# DMASS_PKTDMA_0_DMASS_PKTDMA_0_PKTDMA_FLOWRT_47200000h register map
Vendor: Texas Instruments
Peripheral module from a debugger description file (folder am62L).
Registers are 32-bit, access not given, reset 0x0 unless marked. A register's access mark holds for its fields unless they carry their own. Offsets are as the file gives them; lines under a group give offsets from that group; [hi:lo] are bit positions; {n}, {i} and the like mark numbered series; 'fields as' and 'values as' point back to an identical list; <NAME> marks a mode.

## DMASS_PKTDMA_0_PKTDMA_FLOWRT
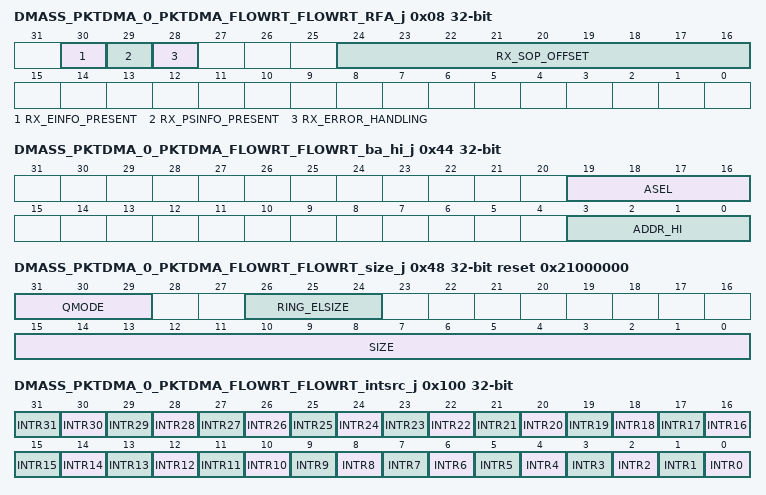
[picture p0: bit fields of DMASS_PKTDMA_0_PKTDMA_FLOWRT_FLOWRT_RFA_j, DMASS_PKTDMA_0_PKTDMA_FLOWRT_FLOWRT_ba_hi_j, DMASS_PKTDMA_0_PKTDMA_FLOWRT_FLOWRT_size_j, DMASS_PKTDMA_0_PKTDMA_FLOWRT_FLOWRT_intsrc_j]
0x08 DMASS_PKTDMA_0_PKTDMA_FLOWRT_FLOWRT_RFA_j rw — The Rx Flow N Configuration Register A contains static configuration information for the Rx DMA flow. The fields in this register can only be changed when all of the DMA channels that use this flow have been disabled. This register is an aliased version from the flow configuration register and is only visible if the alias bit is set in the RESRC register.
  [30] RX_EINFO_PRESENT — This bit controls whether or not the Extended Packet Info Block will be present in the Rx Packet Descriptor. If this bit is clear, the port DMA will clear the Extended Packet Info Present bit in the PD and will drop any Timestamp or SW Data words that are presented from the back end application. If this bit is set, the port DMA will set the Extended Packet Info Block Present bit in the PD and will copy any Timestamp or SW Data words that are presented across the Rx streaming interface into the Extended Packet Info Block words in the descriptor. If no Timestamp or SW Data words are presented from the back end application, the port DMA will overwrite the fields in the PD with zeroes. Reset Source: rst_mod_g_rst_n
  [29] RX_PSINFO_PRESENT — This bit controls whether or not the Protocol Specific words will be present in the Rx Packet Descriptor. If this bit is clear, the port DMA will set the PS word count to 0 in the PD and will drop any PS words that are presented from the back end application. If this bit is set, the port DMA will set the PS word count to the value given by the back end application and will copy the PS words from the back end application to the location Reset Source: rst_mod_g_rst_n
  [28] RX_ERROR_HANDLING — This bit controls the error handling mode for the flow and is only used when channel errors (i.e. descriptor starvation) occurs. 0 = Starvation errors result in dropping packet and incrementing dropped packet count. 1 = Starvation errors result in the channel waiting until descriptors are added to the free queue before the channel will be scheduled. Reset Source: rst_mod_g_rst_n
  [24:16] RX_SOP_OFFSET — This field specifies the number of bytes that are to be skipped in the SOP buffer before beginning to write the payload or protocol specific bytes(if they are in the sop buffer). This value must be less than the minimum size of a buffer in the system. Valid values are 0 - 255 bytes. The primary purpose of this field is to ensure that space is left in the descriptor to place the protocol specific information without overwriting or being overwritten by the Rx data. The secondary purpose of this field is to allow space to be left prior to the data in the descriptor in case header information needs to be added as the packet is passed thorough the system. Reset Source: rst_mod_g_rst_n
0x10 DMASS_PKTDMA_0_PKTDMA_FLOWRT_FLOWRT_fdb_j — The Ring N Doorbell Register is written by software to increment or decrement the number of entries on a Ring. One or more entries as specified by the entry_cnt field can be added to a ring with a single write operation.
  [7:0] ENTRY_CNT — Signed number of entries by which to increment the ring occupancy. For normal Tx Ring operation, this value should be a positive number. This occ value for the ring is increased by this value each time the doorbell register is written (occ absolute value will increase or decrease based on the sign of the ENTRY_CNT). Reset Source: rst_mod_g_rst_n (access NA/W)
0x18 DMASS_PKTDMA_0_PKTDMA_FLOWRT_FLOWRT_focc_j — The Ring N Occupancy Register can be read by software to determine the total number of valid entries on a ring. The contents of each of these registers are unary ORed in order to create a pending signal for the ring which can be used for triggering hardware operations and/or for generating interrupts to the host.
  [16:0] OCC — Total number of valid entries on the ring. This value is generally intended to be incremented by doorbell pokes from software and is decremented by the DMA engine as entries are completed. Reset Source: rst_mod_g_rst_n (access R/NA)
0x40 DMASS_PKTDMA_0_PKTDMA_FLOWRT_FLOWRT_ba_lo_j rw — The Ring Base Address Lo Register contains the 32 LSBs of the base address for the ring which is used to hand off pending work for the channel from the Host. The base address must be aligned to 0x8. A write to this register will reset the associated ring to clear the occupancies and reset the pointers. This register is an aliased version from the flow configuration register and is only visible if the alias bit is set in the RESRC register.
  [31:0] ADDR_LO — Ring base address (LSBs) Reset Source: rst_mod_g_rst_n
0x44 DMASS_PKTDMA_0_PKTDMA_FLOWRT_FLOWRT_ba_hi_j rw — The Ring Base Address Hi Register contains the 16 MSBs of the base address for the ring which is used to hand off pending work for the channel from the Host. The base address must be aligned to 0x8. A write to this register will reset the associated ring to clear the occupancies and reset the pointers. This register is only visible if the alias bit is set in the ring configuration register. This register is an aliased version from the flow configuration register and is only visible if the alias bit is set in the RESRC register.
  [19:16] ASEL — Ring base address select Reset Source: rst_mod_g_rst_n
  [3:0] ADDR_HI — Ring base address (MSBs) Reset Source: rst_mod_g_rst_n
0x48 DMASS_PKTDMA_0_PKTDMA_FLOWRT_FLOWRT_size_j reset 0x21000000 — The Ring Size Register contains the element count for the ring which is used to hand off pending work for the channel from the Host. A write to this register will reset the associated ring to clear the occupancies and reset the pointers. This register is only visible if the alias bit is set in the ring configuration register.
  [31:29] QMODE — Defines the mode for this ring or queue. 1 exposed ring mode with dual queues (forward/reverse) for SW direct access (access R/NA)
  [26:24] RING_ELSIZE — Ring Element size. This field is hardcode as 1 = 8 bytes. Reset Source: rst_mod_g_rst_n (access R/NA)
  [15:0] SIZE rw — This field configures the size of the ring in elements. Reset Source: rst_mod_g_rst_n
0x100 DMASS_PKTDMA_0_PKTDMA_FLOWRT_FLOWRT_intsrc_j — The Interrupt Source shows which of the rings that share the same interrupt as the current ring is setting the interrupt. This register will be the same for all the flows with the same aggregator. The bits are assigned based on the lowest flow number for the aggregator will be in bit 0 and each incremental above will be the next bit. So if flows 5-10 share an interrupt then if flow 5 has a non-zero Masked Cause Register bit 0 will be set. If a ring does not have an interrupt then only bit 0 will be used.
  [n] INTR{n} (n=0..31) — The ring associated with this flow has an active masked interrupt Reset Source: rst_mod_g_rst_n (access R/NA)
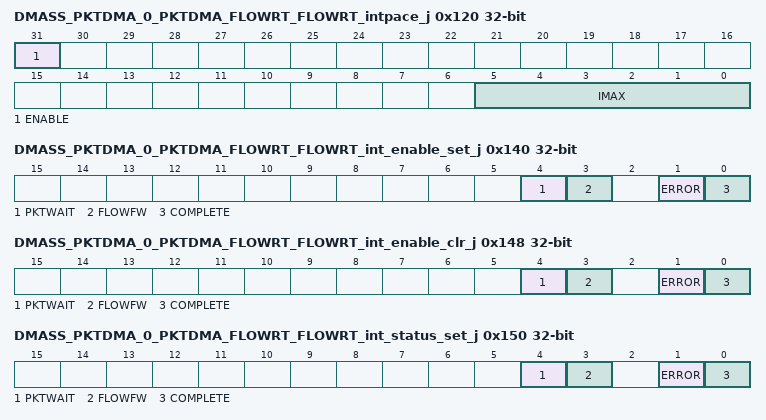
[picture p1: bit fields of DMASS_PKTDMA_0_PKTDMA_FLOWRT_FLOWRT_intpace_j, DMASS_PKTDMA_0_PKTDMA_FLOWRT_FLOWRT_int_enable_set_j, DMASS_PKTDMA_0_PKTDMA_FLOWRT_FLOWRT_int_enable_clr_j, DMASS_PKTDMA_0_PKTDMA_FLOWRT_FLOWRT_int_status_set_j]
0x120 DMASS_PKTDMA_0_PKTDMA_FLOWRT_FLOWRT_intpace_j rw — This register controls the interrupt pacing for the interrupt associated with this flow. This register will only be present if the interrupt supports pacing otherwise it is reserved
  [31] ENABLE — This enables the interrupt pacing module for this interrupt Reset Source: rst_mod_g_rst_n
  [5:0] IMAX — This is the maximum number of interrupts per millisecond generated if the pacing is enabled Reset Source: rst_mod_g_rst_n
0x140 DMASS_PKTDMA_0_PKTDMA_FLOWRT_FLOWRT_int_enable_set_j — The Interrupt Enable Set register is written by software to enable (i.e unmask) specified bits to allow their current status to be considered in the generation of the level sensitive interrupt that is generated by this ring.
  [4] PKTWAIT — Enables the interrupt for a peripheral if it sends data and there is no active descriptor available causing the packet to wait for a new descriptor. This is only valid for an RX flow Reset Source: rst_mod_g_rst_n (access R/W1TS)
  [3] FLOWFW — Enables the interrupt for the peripheral sending a flow id to the channel used by this flow is outside the range assigned to the channel. This field is only valid for an RX flow that supports packet descriptors Reset Source: rst_mod_g_rst_n (access R/W1TS)
  [1] ERROR — Enables the interrupt for the flow having an error during the transfer. Reset Source: rst_mod_g_rst_n (access R/W1TS)
  [0] COMPLETE — Enables the intterupt for the flow completing a descriptor and placing it on the reverse ring Reset Source: rst_mod_g_rst_n (access R/W1TS)
0x148 DMASS_PKTDMA_0_PKTDMA_FLOWRT_FLOWRT_int_enable_clr_j — The Interrupt Enable Clear register is written by software to disable (i.e mask) specified bits to allow their current status to be ignored in the generation of the level sensitive interrupt that is generated by this ring.
  [4] PKTWAIT — Disables the interrupt for a peripheral if it sends data and there is no active descriptor available causing the packet to wait for a new descriptor. This is only valid for an RX flow Reset Source: rst_mod_g_rst_n (access R/W1TC)
  [3] FLOWFW — Disables the interrupt for the peripheral sending a flow id to the channel used by this flow is outside the range assigned to the channel. This field is only valid for an RX flow that supports packet descriptors Reset Source: rst_mod_g_rst_n (access R/W1TC)
  [1] ERROR — Disables the interrupt for the flow having an error during the transfer. Reset Source: rst_mod_g_rst_n (access R/W1TC)
  [0] COMPLETE — Disables the interupt for the flow completing a descriptor and placing it on the reverse ring Reset Source: rst_mod_g_rst_n (access R/W1TC)
0x150 DMASS_PKTDMA_0_PKTDMA_FLOWRT_FLOWRT_int_status_set_j — The Interrupt Status register is read by software to determine the cause of the level sensitive interrupt that is generated by this ring.
  [4] PKTWAIT — A peripheral sent data and there was no active descriptor available causing the packet to wait for a new descriptor. This is only valid for an RX flow. This bit can be cleared by writing a one to this bit. Reset Source: rst_mod_g_rst_n (access R/W1TS)
  [3] FLOWFW — The peripheral sent a flow id to the channel used by this flow outside the range assigned to the channel. This field is only valid for an RX flow that supports packet descriptors. This bit can be cleared by clearing the RX Flow ID Firewalll Status Register Reset Source: rst_mod_g_rst_n (access R/W1TS)
  [1] ERROR — The flow encountered an error during the transfer. This bit can be cleared by writing a 1. Reset Source: rst_mod_g_rst_n (access R/W1TS)
  [0] COMPLETE — The reverse ring occupancy is non-zero. This can be cleared by emptying the reverse ring by writing to the reverse doorbell to make the occupancy zero. Reset Source: rst_mod_g_rst_n (access R/W1TS)
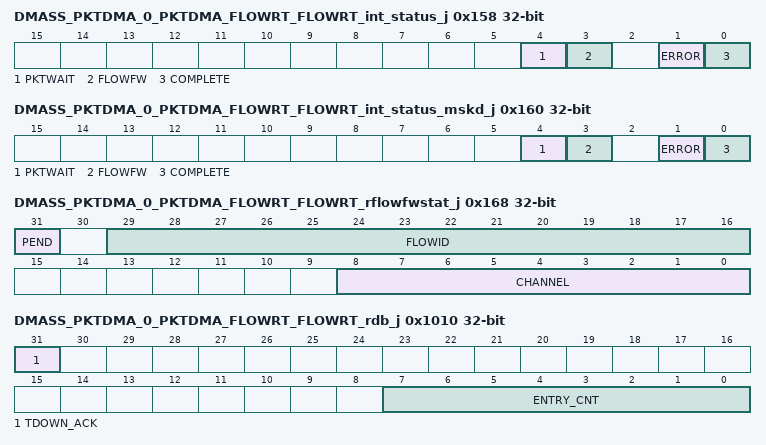
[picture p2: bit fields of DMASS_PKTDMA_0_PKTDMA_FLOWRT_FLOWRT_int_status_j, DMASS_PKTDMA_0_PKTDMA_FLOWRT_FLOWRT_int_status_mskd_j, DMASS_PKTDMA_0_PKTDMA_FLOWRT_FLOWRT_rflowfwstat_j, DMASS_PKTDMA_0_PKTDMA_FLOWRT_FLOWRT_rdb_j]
0x158 DMASS_PKTDMA_0_PKTDMA_FLOWRT_FLOWRT_int_status_j — The Interrupt Status register is read by software to determine the cause of the level sensitive interrupt that is generated by this ring.
  [4] PKTWAIT — A peripheral sent data and there was no active descriptor available causing the packet to wait for a new descriptor. This is only valid for an RX flow. This bit can be cleared by writing a one to this bit. Reset Source: rst_mod_g_rst_n (access R/W1TC)
  [3] FLOWFW — The peripheral sent a flow id to the channel used by this flow outside the range assigned to the channel. This field is only valid for an RX flow that supports packet descriptors. This bit can be cleared by clearing the RX Flow ID Firewalll Status Register Reset Source: rst_mod_g_rst_n (access R/W1TC)
  [1] ERROR — The flow encountered an error during the transfer. This bit can be cleared by writing a 1. Reset Source: rst_mod_g_rst_n (access R/W1TC)
  [0] COMPLETE — The reverse ring occupancy is non-zero. This can be cleared by emptying the reverse ring by writing to the reverse doorbell to make the occupancy zero. Reset Source: rst_mod_g_rst_n (access R/W1TC)
0x160 DMASS_PKTDMA_0_PKTDMA_FLOWRT_FLOWRT_int_status_mskd_j ro — The Interrupt Status Masked register is the bitwise AND of the INT_ENABLE register and the INT_STATUS REGISTER. It can be read by software to determine the cause of the level sensitive interrupt that is generated by this ring.
  [4] PKTWAIT — A peripheral sent data and there was no active descriptor available causing the packet to wait for a new descriptor. This is only valid for an RX flow. Reset Source: rst_mod_g_rst_n
  [3] FLOWFW — The peripheral sent a flow id to the channel used by this flow outside the range assigned to the channel. This field is only valid for an RX flow that supports packet descriptors. This bit can be cleared by clearing the RX Flow ID Firewalll Status Register Reset Source: rst_mod_g_rst_n
  [1] ERROR — The flow encountered an error during the transfer. Reset Source: rst_mod_g_rst_n
  [0] COMPLETE — The reverse ring occupancy is non-zero. This can be cleared by emptying the reverse ring by writing to the reverse doorbell to make the occupancy zero. Reset Source: rst_mod_g_rst_n
0x168 DMASS_PKTDMA_0_PKTDMA_FLOWRT_FLOWRT_rflowfwstat_j — The Rx Flow FW Status Register 0 captures information about the thread/channel and received flow ID which failed a range check. Values in this register will remain persistent once an exception has been detected until the pend bit is written back to 0. This register is the same for all flows so it must be cleared to enable capturing future errors.
  [31] PEND — This bit is set whenever the Flow ID firewall detects a Flow ID is out of range for an incoming packet. Once this bit is set, the remaining fields in this register will not be modified. SW is required to write this bit to 0 to allow another exception to be captured. Reset Source: rst_mod_g_rst_n (access R/W0TC)
  [29:16] FLOWID ro — This is the flow ID that was received on the trapped packet Reset Source: rst_mod_g_rst_n
  [8:0] CHANNEL ro — This is the channel number on which the trapped packet was received Reset Source: rst_mod_g_rst_n
0x1010 DMASS_PKTDMA_0_PKTDMA_FLOWRT_FLOWRT_rdb_j — The Ring N Doorbell Register is written by software to increment or decrement the number of entries on a Ring. One or more entries as specified by the entry_cnt field can be added to a ring with a single write operation.
  [31] TDOWN_ACK — This bit is set to 1 to ackowledge (and clear) the tdown_complete bit in the corresponding Ring N Occupancy Register. this bit is only valid on the reverse rings (rings consumed by the Host SW) Reset Source: rst_mod_g_rst_n (access NA/W)
  [7:0] ENTRY_CNT — Signed number of entries by which to increment the ring occupancy. For normal Ring operation, this value should be a positive number. This occ value for the ring is increased by this value each time the doorbell register is written (occ absolute value will increase or decrease based on the sign of the ENTRY_CNT). Reset Source: rst_mod_g_rst_n (access NA/W)
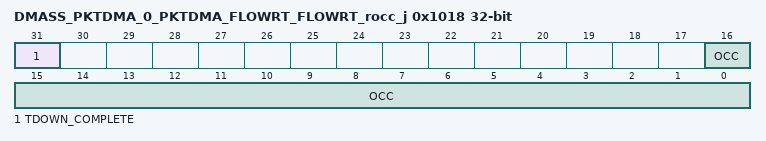
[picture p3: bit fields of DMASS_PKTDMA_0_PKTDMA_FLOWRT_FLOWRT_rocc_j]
0x1018 DMASS_PKTDMA_0_PKTDMA_FLOWRT_FLOWRT_rocc_j — The Ring N Occupancy Register can be read by software to determine the total number of valid entries on a ring. The contents of each of these registers are unary ORed in order to create a pending signal for the ring which can be used for triggering hardware operations and/or for generating interrupts to the host.
  [31] TDOWN_COMPLETE — This bit when set indicates that a teardown is complete on the channel. This bit is cleared anytime the tdown_ack bit is written as a 1 in the corresponding Ring N Doorbell Register. This bit is only valid on the reverse rings (rings consumed by the Host SW). Reset Source: rst_mod_g_rst_n (access R/NA)
  [16:0] OCC — Total number of valid entries on the ring. This value is generally intended to be incremented by doorbell pokes from software and is decremented by the DMA engine as entries are completed. Reset Source: rst_mod_g_rst_n (access R/NA)
